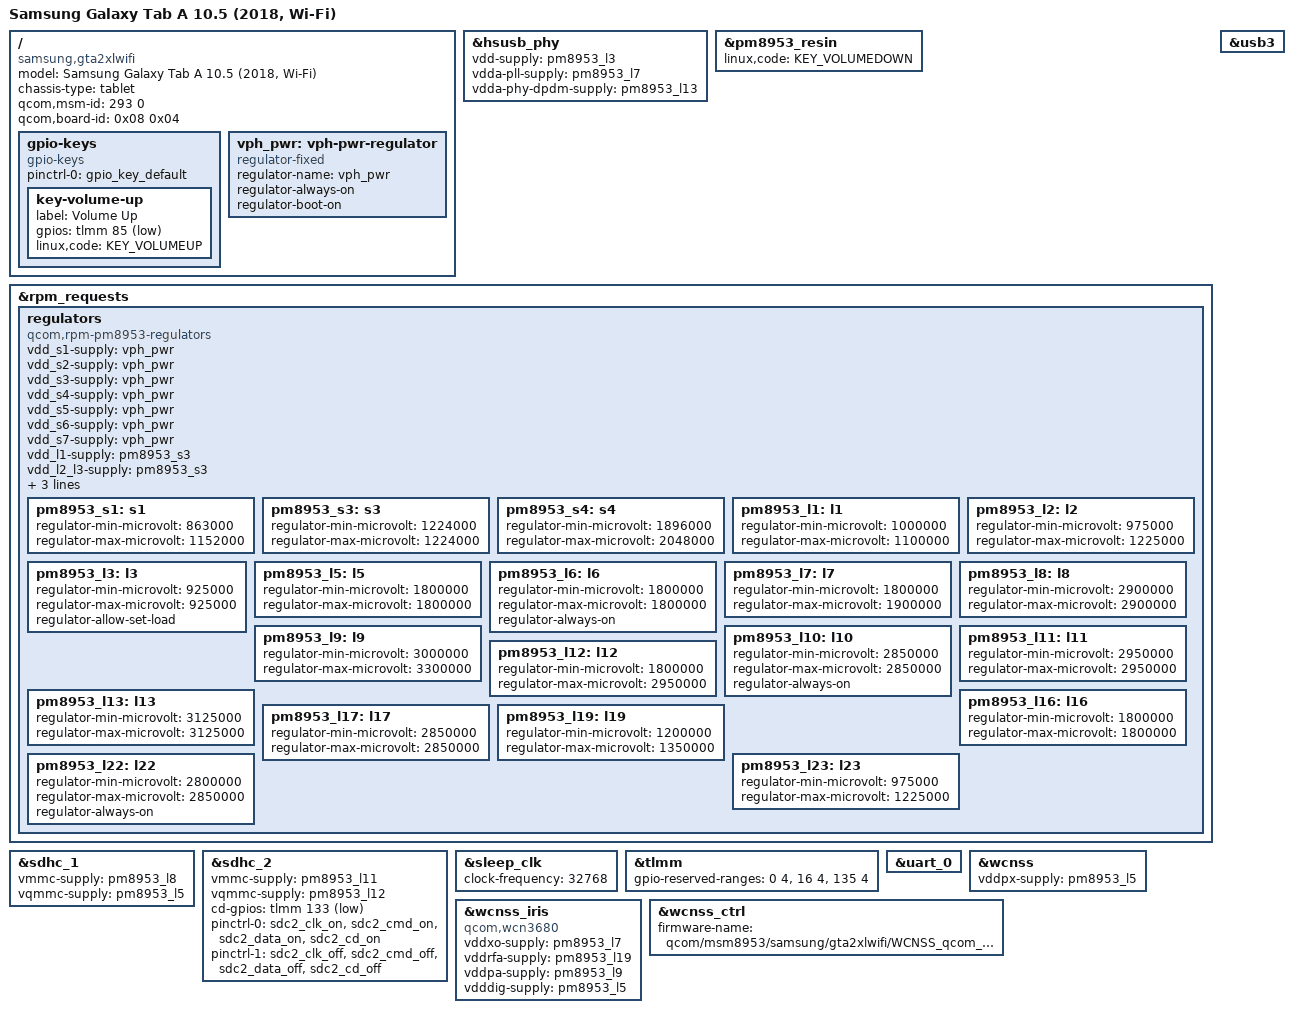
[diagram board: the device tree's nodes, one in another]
// SPDX-License-Identifier: BSD-3-Clause
/*
 * Copyright (c) 2026, Simon <m8l8th814n@gmail.com>
 */

/dts-v1/;

#include "msm8953.dtsi"
#include "pm8953.dtsi"

/*
 * Samsung Galaxy Tab A 10.5 (2018, Wi-Fi) — "gta2xlwifi".
 * This board pairs the MSM8953 with a PM8953 only (no PMI8950/PMI8937).
 */

/ {
	model = "Samsung Galaxy Tab A 10.5 (2018, Wi-Fi)";
	compatible = "samsung,gta2xlwifi", "qcom,msm8953";
	chassis-type = "tablet";

	qcom,msm-id = <293 0>;
	qcom,board-id = <0x08 0x04>;

	gpio-keys {
		compatible = "gpio-keys";

		pinctrl-names = "default";
		pinctrl-0 = <&gpio_key_default>;

		key-volume-up {
			label = "Volume Up";
			gpios = <&tlmm 85 GPIO_ACTIVE_LOW>;
			linux,code = <KEY_VOLUMEUP>;
		};
	};

	vph_pwr: vph-pwr-regulator {
		compatible = "regulator-fixed";
		regulator-name = "vph_pwr";
		regulator-always-on;
		regulator-boot-on;
	};
};

&hsusb_phy {
	vdd-supply = <&pm8953_l3>;
	vdda-pll-supply = <&pm8953_l7>;
	vdda-phy-dpdm-supply = <&pm8953_l13>;

	status = "okay";
};

&pm8953_resin {
	linux,code = <KEY_VOLUMEDOWN>;
	status = "okay";
};

&rpm_requests {
	regulators {
		compatible = "qcom,rpm-pm8953-regulators";

		vdd_s1-supply = <&vph_pwr>;
		vdd_s2-supply = <&vph_pwr>;
		vdd_s3-supply = <&vph_pwr>;
		vdd_s4-supply = <&vph_pwr>;
		vdd_s5-supply = <&vph_pwr>;
		vdd_s6-supply = <&vph_pwr>;
		vdd_s7-supply = <&vph_pwr>;
		vdd_l1-supply = <&pm8953_s3>;
		vdd_l2_l3-supply = <&pm8953_s3>;
		vdd_l4_l5_l6_l7_l16_l19-supply = <&pm8953_s4>;
		vdd_l8_l11_l12_l13_l14_l15-supply = <&vph_pwr>;
		vdd_l9_l10_l17_l18_l22-supply = <&vph_pwr>;

		pm8953_s1: s1 {
			regulator-min-microvolt = <863000>;
			regulator-max-microvolt = <1152000>;
		};

		pm8953_s3: s3 {
			regulator-min-microvolt = <1224000>;
			regulator-max-microvolt = <1224000>;
		};

		pm8953_s4: s4 {
			regulator-min-microvolt = <1896000>;
			regulator-max-microvolt = <2048000>;
		};

		pm8953_l1: l1 {
			regulator-min-microvolt = <1000000>;
			regulator-max-microvolt = <1100000>;
		};

		pm8953_l2: l2 {
			regulator-min-microvolt = <975000>;
			regulator-max-microvolt = <1225000>;
		};

		pm8953_l3: l3 {
			regulator-min-microvolt = <925000>;
			regulator-max-microvolt = <925000>;
			regulator-allow-set-load;
		};

		pm8953_l5: l5 {
			regulator-min-microvolt = <1800000>;
			regulator-max-microvolt = <1800000>;
		};

		pm8953_l6: l6 {
			regulator-min-microvolt = <1800000>;
			regulator-max-microvolt = <1800000>;
			regulator-always-on;
		};

		pm8953_l7: l7 {
			regulator-min-microvolt = <1800000>;
			regulator-max-microvolt = <1900000>;
		};

		pm8953_l8: l8 {
			regulator-min-microvolt = <2900000>;
			regulator-max-microvolt = <2900000>;
		};

		pm8953_l9: l9 {
			regulator-min-microvolt = <3000000>;
			regulator-max-microvolt = <3300000>;
		};

		pm8953_l10: l10 {
			regulator-min-microvolt = <2850000>;
			regulator-max-microvolt = <2850000>;
			regulator-always-on;
		};

		pm8953_l11: l11 {
			regulator-min-microvolt = <2950000>;
			regulator-max-microvolt = <2950000>;
		};

		pm8953_l12: l12 {
			regulator-min-microvolt = <1800000>;
			regulator-max-microvolt = <2950000>;
		};

		pm8953_l13: l13 {
			regulator-min-microvolt = <3125000>;
			regulator-max-microvolt = <3125000>;
		};

		pm8953_l16: l16 {
			regulator-min-microvolt = <1800000>;
			regulator-max-microvolt = <1800000>;
		};

		pm8953_l17: l17 {
			regulator-min-microvolt = <2850000>;
			regulator-max-microvolt = <2850000>;
		};

		pm8953_l19: l19 {
			regulator-min-microvolt = <1200000>;
			regulator-max-microvolt = <1350000>;
		};

		pm8953_l22: l22 {
			regulator-min-microvolt = <2800000>;
			regulator-max-microvolt = <2850000>;
			regulator-always-on;
		};

		pm8953_l23: l23 {
			regulator-min-microvolt = <975000>;
			regulator-max-microvolt = <1225000>;
		};
	};
};

&sdhc_1 {
	vmmc-supply = <&pm8953_l8>;
	vqmmc-supply = <&pm8953_l5>;

	status = "okay";
};

&sdhc_2 {
	vmmc-supply = <&pm8953_l11>;
	vqmmc-supply = <&pm8953_l12>;

	cd-gpios = <&tlmm 133 GPIO_ACTIVE_LOW>;

	pinctrl-names = "default", "sleep";
	pinctrl-0 = <&sdc2_clk_on &sdc2_cmd_on &sdc2_data_on &sdc2_cd_on>;
	pinctrl-1 = <&sdc2_clk_off &sdc2_cmd_off &sdc2_data_off &sdc2_cd_off>;

	status = "okay";
};

&sleep_clk {
	clock-frequency = <32768>;
};

&tlmm {
	gpio-reserved-ranges = <0 4>, <16 4>, <135 4>;
};

&uart_0 {
	status = "okay";
};

&usb3 {
	status = "okay";
};

&wcnss {
	status = "okay";

	vddpx-supply = <&pm8953_l5>;
};

&wcnss_iris {
	compatible = "qcom,wcn3680";

	vddxo-supply = <&pm8953_l7>;
	vddrfa-supply = <&pm8953_l19>;
	vddpa-supply = <&pm8953_l9>;
	vdddig-supply = <&pm8953_l5>;
};

&wcnss_ctrl {
	firmware-name = "qcom/msm8953/samsung/gta2xlwifi/WCNSS_qcom_wlan_nv.bin";
};
